# DMASS_PKTDMA_0_DMASS_PKTDMA_0_PKTDMA_GCFG_485C0000h register map
Vendor: Texas Instruments
Peripheral module from a debugger description file (folder am62L).
Registers are 32-bit, read-write, reset 0x0 unless marked. A register's access mark holds for its fields unless they carry their own. Offsets are as the file gives them; lines under a group give offsets from that group; [hi:lo] are bit positions; {n}, {i} and the like mark numbered series; 'fields as' and 'values as' point back to an identical list; <NAME> marks a mode.

## DMASS_PKTDMA_0_PKTDMA_GCFG
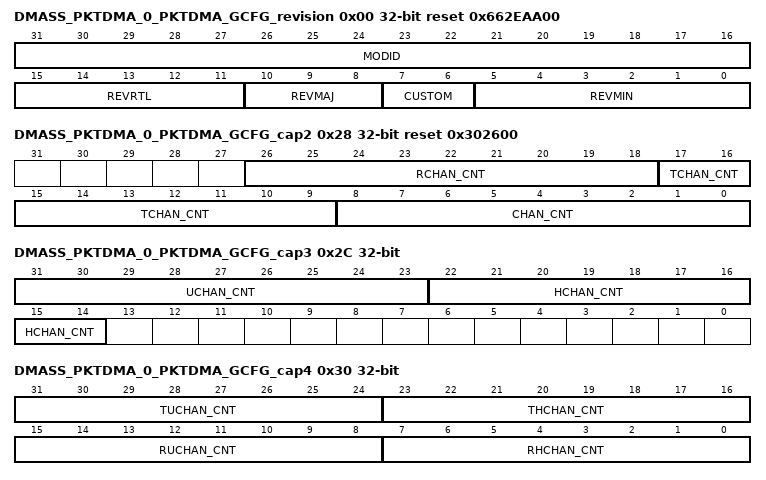
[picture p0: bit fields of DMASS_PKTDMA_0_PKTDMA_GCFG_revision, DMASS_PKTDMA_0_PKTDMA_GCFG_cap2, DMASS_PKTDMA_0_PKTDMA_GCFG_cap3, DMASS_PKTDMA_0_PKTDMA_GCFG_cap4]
0x00 DMASS_PKTDMA_0_PKTDMA_GCFG_revision ro reset 0x662EAA00 — The Revision Register contains the major and minor revisions for the module.
  [31:16] MODID — Module ID field Reset Source: rst_mod_g_rst_n
  [15:11] REVRTL — RTL revision. Will vary depending on release. Reset Source: rst_mod_g_rst_n
  [10:8] REVMAJ — Major revision Reset Source: rst_mod_g_rst_n
  [7:6] CUSTOM — Custom Reset Source: rst_mod_g_rst_n
  [5:0] REVMIN — Minor revision Reset Source: rst_mod_g_rst_n
0x20 DMASS_PKTDMA_0_PKTDMA_GCFG_cap0 access not given reset not defined — The Capabilities Register 0 specifies which standard features this PKTDMA instance supports.
0x24 DMASS_PKTDMA_0_PKTDMA_GCFG_cap1 access not given reset not defined — The Capabilities Register 1 specifies which standard features this PKTDMA instance supports.
0x28 DMASS_PKTDMA_0_PKTDMA_GCFG_cap2 ro reset 0x302600 — The Capabilities Register 2 specifies how many resources this PKTDMA instance supports.
  [26:18] RCHAN_CNT — Rx split channel count including high capacity and ultra high capacity Reset Source: rst_mod_g_rst_n
  [17:9] TCHAN_CNT — Tx split channel count including high capacity and ultra high capacity Reset Source: rst_mod_g_rst_n
  [8:0] CHAN_CNT — BC channel count including high capacity and ultra high capacity Reset Source: rst_mod_g_rst_n
0x2C DMASS_PKTDMA_0_PKTDMA_GCFG_cap3 ro — The Capabilities Register 3 specifies how many resources this PKTDMA instance supports.
  [31:23] UCHAN_CNT — BC ultra high capacity internal channel count Reset Source: rst_mod_g_rst_n
  [22:14] HCHAN_CNT — BC high capacity internal channel count Reset Source: rst_mod_g_rst_n
0x30 DMASS_PKTDMA_0_PKTDMA_GCFG_cap4 ro — The Capabilities Register 4 specifies how many resources this PKTDMA instance supports.
  [31:24] TUCHAN_CNT — TX ultra high capacity internal channel count Reset Source: rst_mod_g_rst_n
  [23:16] THCHAN_CNT — TX high capacity internal channel count Reset Source: rst_mod_g_rst_n
  [15:8] RUCHAN_CNT — RX ultra high capacity internal channel count Reset Source: rst_mod_g_rst_n
  [7:0] RHCHAN_CNT — RX high capacity internal channel count Reset Source: rst_mod_g_rst_n
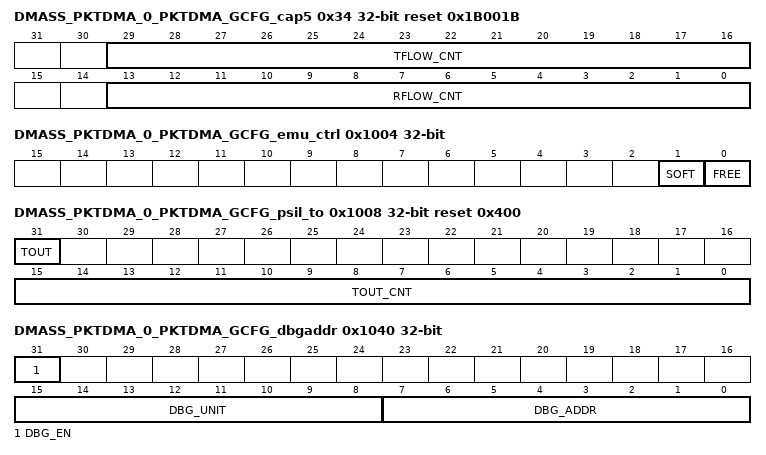
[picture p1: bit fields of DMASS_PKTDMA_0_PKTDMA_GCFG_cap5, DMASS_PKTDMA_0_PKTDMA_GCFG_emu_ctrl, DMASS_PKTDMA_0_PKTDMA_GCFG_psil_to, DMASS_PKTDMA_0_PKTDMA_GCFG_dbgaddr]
0x34 DMASS_PKTDMA_0_PKTDMA_GCFG_cap5 ro reset 0x1B001B — The Capabilities Register 5 specifies how many flows this PKTDMA instance supports.
  [29:16] TFLOW_CNT — Tx flow table entry count Reset Source: rst_mod_g_rst_n
  [13:0] RFLOW_CNT — Rx flow table entry count Reset Source: rst_mod_g_rst_n
0x1000 DMASS_PKTDMA_0_PKTDMA_GCFG_perf_ctrl reset 0x40 — The performance control register contains fields which can be used to adjust the performance of the PKTDMA in the system.
  [15:0] TIMEOUT_CNT — This feature is not currently supported. Reset Source: rst_mod_g_rst_n
0x1004 DMASS_PKTDMA_0_PKTDMA_GCFG_emu_ctrl — The emulation control register is used to control the behavior of the DMA when the emususp input is asserted.
  [1] SOFT — Soft Reset Source: rst_mod_g_rst_n
  [0] FREE — Free Reset Source: rst_mod_g_rst_n
0x1008 DMASS_PKTDMA_0_PKTDMA_GCFG_psil_to reset 0x400 — The PSI-L proxy timeout register controls the timeout watchdog and reports timeout occurrances on PSI-L configuration transactions issued by the built in PSI-L proxy.
  [31] TOUT — Timeout occurred. When set indicates that a timeout has occurred on a config access Reset Source: rst_mod_g_rst_n
  [15:0] TOUT_CNT — Timeout period. Specifies how many cycles to wait before closing up a conifiguration read or write transaction and asserting the tout bit Reset Source: rst_mod_g_rst_n
0x1040 DMASS_PKTDMA_0_PKTDMA_GCFG_dbgaddr — This register provides a writable address which allows debug information to be read from the Debug Data Register
  [31] DBG_EN — Debug enable Reset Source: rst_mod_g_rst_n
  [15:8] DBG_UNIT — Selects which unit to read debug information from 18 Read response tracking engine35 Write response tracking engine80 Scheduling configuration engine176 TX scheduling unit 0177 TX scheduling unit 1178 TX scheduling unit 2179 TX scheduling unit 3192 RX scheduling unit 0193 RX scheduling unit 1194 RX scheduling unit 2195 RX scheduling unit 3
  [7:0] DBG_ADDR — Selects offset within unit to access seperate debug registers Reset Source: rst_mod_g_rst_n
0x1044 DMASS_PKTDMA_0_PKTDMA_GCFG_dbgdata access not given — This register provides read only debug data
  [31:0] DBG_DATA — Provides debug information from various internal units. The value which is read back depends on which unit and register are selected in the Debug Address Register Reset Source: rst_mod_g_rst_n (access R/NA)
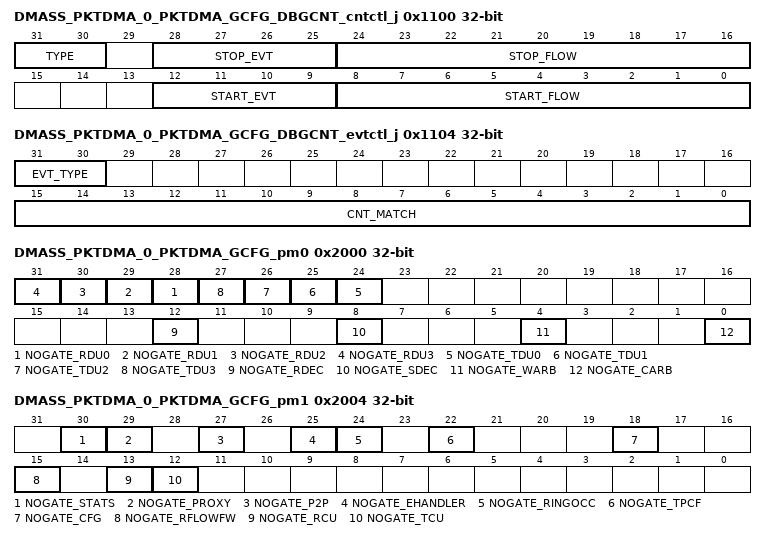
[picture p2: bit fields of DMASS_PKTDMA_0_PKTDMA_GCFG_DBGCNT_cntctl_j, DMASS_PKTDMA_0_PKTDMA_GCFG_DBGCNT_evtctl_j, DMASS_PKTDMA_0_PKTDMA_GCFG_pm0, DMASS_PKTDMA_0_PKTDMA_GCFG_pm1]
0x1100 DMASS_PKTDMA_0_PKTDMA_GCFG_DBGCNT_cntctl_j — The debug counter control to select how the associated counter is incremented and starts and stops. Writing to this register will reset the counter.
  [31:30] TYPE — Selects what type of counter the Debug Counter is used. 0 Increment counter the start selected event increment the counter on each rising edge.1 One shot cycle count the first time the rising edge start count is generated and stops when the stop event rising edge is seen. If additional start events are seen the counter will not change. The counter will not roll over.2 Continous cycle count the counter counts cycles when start event rising edge is seen and stops when stop rising edge is seen and starts again when the start event rising edge is seen. The counter will not roll over.
  [28:25] STOP_EVT — The event type to use for the timer. The event will be the event from the given flow in the stop flow field. 0 A scheduling request is sent to a scheduling unit for the flow1 A read command is sent for the flow2 A write command is sent for the flow3 A read data response is received for the flow4 A write data response is received for the flow5 The read data response for the last request of the TR/PKT has been received6 The write data response for the last request of the TR/PKT has been received8
  [24:16] STOP_FLOW — The flow number that generates the event to start or increment the counter Reset Source: rst_mod_g_rst_n
  [12:9] START_EVT — The event type to use for the timer. The event will be the event from the given flow in the start flow field. 0 A scheduling request is sent to a scheduling unit for the flow1 A read command is sent for the flow2 A write command is sent for the flow3 A read data response is received for the flow4 A write data response is received for the flow5 The data read response for the last request of the TR/PKT has been received6 The data write response for the last request of the TR/PKT has been received8
  [8:0] START_FLOW — The flow number that generates the event to start or increment the counter Reset Source: rst_mod_g_rst_n
0x1104 DMASS_PKTDMA_0_PKTDMA_GCFG_DBGCNT_evtctl_j — The debug event control to select when the debug controller can issue an event that can be used by another debug event control. Writing to this register will reset the counter.
  [31:30] EVT_TYPE — Selects when or if an event will be generated by the counter. 0 No event is generated.1 Exact match.2 The counter is bit-wise ANDed with the cnt match and the event is when this mask is non-zero.
  [15:0] CNT_MATCH — The value that if set the counter generates an event. It can also be used as a mask based on event type Reset Source: rst_mod_g_rst_n
0x1108 DMASS_PKTDMA_0_PKTDMA_GCFG_DBGCNT_cnt_j ro — The actual counter that is incremented or free running based on the event control registers
  [15:0] CNT — The count value of the debug counter Reset Source: rst_mod_g_rst_n
0x2000 DMASS_PKTDMA_0_PKTDMA_GCFG_pm0 — This register enables or inhibits automatic clock gating to individual sub-blocks
  [n+28] NOGATE_RDU{n} (n=0..3) — When set inhibits automatic gating of clock to rdu{n} submodule. Reset Source: rst_mod_g_rst_n
  [n+24] NOGATE_TDU{n} (n=0..3) — When set inhibits automatic gating of clock to tdu{n} submodule. Reset Source: rst_mod_g_rst_n
  [12] NOGATE_RDEC — When set inhibits automatic gating of clock to rdec submodule. Reset Source: rst_mod_g_rst_n
  [8] NOGATE_SDEC — When set inhibits automatic gating of clock to sdec submodule. Reset Source: rst_mod_g_rst_n
  [4] NOGATE_WARB — When set inhibits automatic gating of clock to warb submodule. Reset Source: rst_mod_g_rst_n
  [0] NOGATE_CARB — When set inhibits automatic gating of clock to carb submodule. Reset Source: rst_mod_g_rst_n
0x2004 DMASS_PKTDMA_0_PKTDMA_GCFG_pm1 — This register enables or inhibits automatic clock gating to individual sub-blocks
  [30] NOGATE_STATS — When set inhibits automatic gating of clock to stats submodule. Reset Source: rst_mod_g_rst_n
  [29] NOGATE_PROXY — When set inhibits automatic gating of clock to proxy submodule. Reset Source: rst_mod_g_rst_n
  [27] NOGATE_P2P — When set inhibits automatic gating of clock to p2p submodule. Reset Source: rst_mod_g_rst_n
  [25] NOGATE_EHANDLER — When set inhibits automatic gating of clock to ehandler submodule. Reset Source: rst_mod_g_rst_n
  [24] NOGATE_RINGOCC — When set inhibits automatic gating of clock to ringocc submodule. Reset Source: rst_mod_g_rst_n
  [22] NOGATE_TPCF — When set inhibits automatic gating of clock to tpcf submodule. Reset Source: rst_mod_g_rst_n
  [18] NOGATE_CFG — When set inhibits automatic gating of clock to cfg submodule. Reset Source: rst_mod_g_rst_n
  [15] NOGATE_RFLOWFW — When set inhibits automatic gating of clock to rflowfw submodule. Reset Source: rst_mod_g_rst_n
  [13] NOGATE_RCU — When set inhibits automatic gating of clock to rcu submodule. Reset Source: rst_mod_g_rst_n
  [12] NOGATE_TCU — When set inhibits automatic gating of clock to tcu submodule. Reset Source: rst_mod_g_rst_n
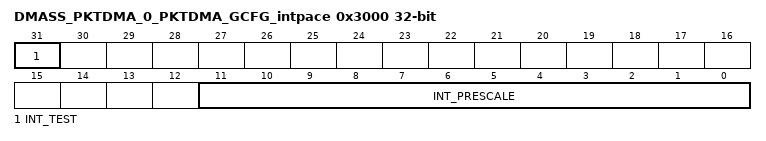
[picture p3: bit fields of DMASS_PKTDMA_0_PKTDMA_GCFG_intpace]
0x3000 DMASS_PKTDMA_0_PKTDMA_GCFG_intpace — This register contains the shared fields used by all the interrupt pacing modules
  [31] INT_TEST — Test bit to the interrupt pacing blocks. Reset Source: rst_mod_g_rst_n
  [11:0] INT_PRESCALE — The number of VBUSP_CLK periods in 4us. The reset value is set based on int_pace_prescale_ipcfg[11:0] tieoff pin Reset Source: rst_mod_g_rst_n
